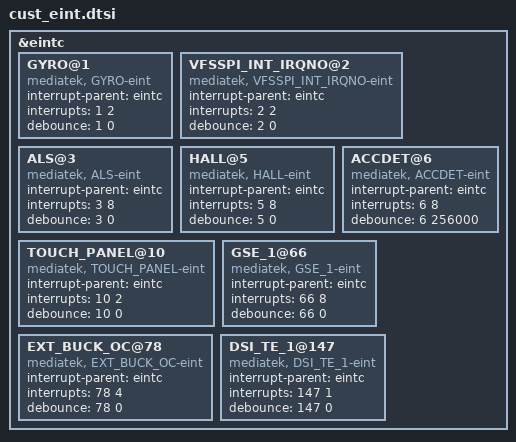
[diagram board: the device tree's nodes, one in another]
/*
 * Generated by MTK SP DrvGen Version 03.13.6 for MT6753. Copyright MediaTek Inc. (C) 2013.
 * Fri Oct 09 12:15:02 2015
 * Do Not Modify the File.
 */

/*************************
 * EINT DTSI File
*************************/

&eintc {
	GYRO@1 {
		compatible = "mediatek, GYRO-eint";
		interrupt-parent = <&eintc>;
		interrupts = <1 2>;
		debounce = <1 0>;
	};

	VFSSPI_INT_IRQNO@2 {
		compatible = "mediatek, VFSSPI_INT_IRQNO-eint";
		interrupt-parent = <&eintc>;
		interrupts = <2 2>;
		debounce = <2 0>;
	};

	ALS@3 {
		compatible = "mediatek, ALS-eint";
		interrupt-parent = <&eintc>;
		interrupts = <3 8>;
		debounce = <3 0>;
	};

	HALL@5 {
		compatible = "mediatek, HALL-eint";
		interrupt-parent = <&eintc>;
		interrupts = <5 8>;
		debounce = <5 0>;
	};

	ACCDET@6 {
		compatible = "mediatek, ACCDET-eint";
		interrupt-parent = <&eintc>;
		interrupts = <6 8>;
		debounce = <6 256000>;
	};

	TOUCH_PANEL@10 {
		compatible = "mediatek, TOUCH_PANEL-eint";
		interrupt-parent = <&eintc>;
		interrupts = <10 2>;
		debounce = <10 0>;
	};

	GSE_1@66 {
		compatible = "mediatek, GSE_1-eint";
		interrupt-parent = <&eintc>;
		interrupts = <66 8>;
		debounce = <66 0>;
	};

	EXT_BUCK_OC@78 {
		compatible = "mediatek, EXT_BUCK_OC-eint";
		interrupt-parent = <&eintc>;
		interrupts = <78 4>;
		debounce = <78 0>;
	};

	DSI_TE_1@147 {
		compatible = "mediatek, DSI_TE_1-eint";
		interrupt-parent = <&eintc>;
		interrupts = <147 1>;
		debounce = <147 0>;
	};

};
